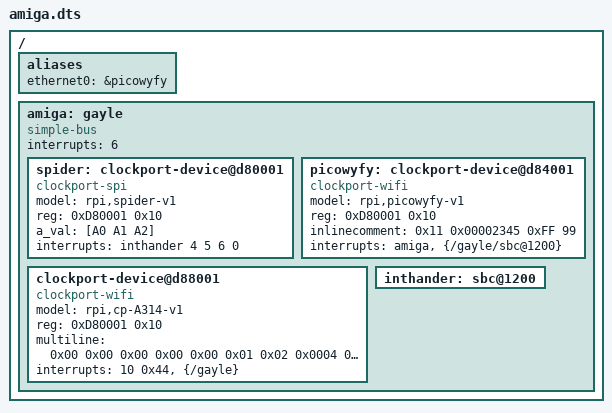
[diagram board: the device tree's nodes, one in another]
/dts-v1/;

/* 	
	DTS style hardware configuration for Commodore Amiga.
	Format is a sub-set of the DTS without some capabilities.
	The /include/ directive does work. /delete-node/ and /delete-property/
	are not implemented (you can just comment out if not needed.
	/dts-v1/ is not required but useful to auto-identify file format in AmigaOS.
	Labels are supported for nodes and properties. Don't use in values. 
*/

/memreserve/ 0x10000000 0x4000;

/ {
	aliases {
		ethernet0 = &picowyfy;
	};
	
	amiga: gayle{
		phandle = <59>;
		compatible = "simple-bus";
		ranges;
		interrupts = <6>;

		spider: clockport-device@d80001 {
			compatible = "clockport-spi";
			model = "rpi,spider-v1";
			reg = <0xD80001 0x10>;
			a_val = [A0 // A thing
			        A1 // another thing
					A2];
			interrupts = <&inthander 4 5 6 0>;
		};
		
		picowyfy: clockport-device@d84001 {
			compatible = "clockport-wifi";
			phandle = <3>;
			model = "rpi,picowyfy-v1";
			reg = <0xD80001 0x10>;
			inlinecomment = <0x11 0x00002345 /* Comment */ 0xFF 99>;
			
			interrupts = <&amiga &{/gayle/sbc@1200}>;
		};
		
		cp-314: clockport-device@d88001 {
			compatible = "clockport-wifi", "clockport-spi", "clockport-storage";
			model = "rpi,cp-A314-v1";
			reg = <0xD80001 0x10>;
			multiline = <0x00 0x00 0x00 0x00 0x00 /* stuff */
			             0x01 0x02 0x0004 0x0005 0x06>; /* and nonsense */
						 
			interrupts = <10 0x44 &{/gayle}>;
		};
		
		inthander: sbc@1200{
			phandle = <1>;
		};
		
	};
};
